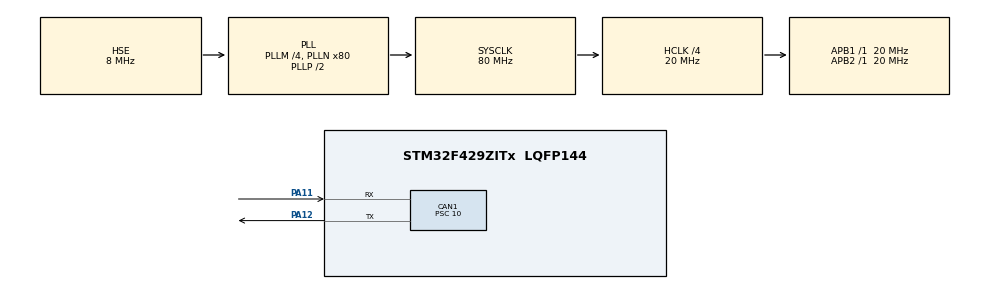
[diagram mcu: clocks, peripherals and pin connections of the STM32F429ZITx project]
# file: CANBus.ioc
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Mcu.Family=STM32F4
RCC.PLLSourceVirtual=RCC_PLLSOURCE_HSE
RCC.CortexFreq_Value=20000000
CAN1.CalculateBaudRate=125000
PA11.Mode=CAN_Activate
RCC.SYSCLKSource=RCC_SYSCLKSOURCE_PLLCLK
ProjectManager.StackSize=0x400
PA13.Signal=SYS_JTMS-SWDIO
PA12.Signal=CAN1_TX
CAN1.BS2=CAN_BS2_6TQ
CAN1.BS1=CAN_BS1_9TQ
ProjectManager.TargetToolchain=STM32CubeIDE
PH0/OSC_IN.Mode=HSE-External-Clock-Source
RCC.HCLKFreq_Value=20000000
RCC.APB2TimFreq_Value=20000000
PH1/OSC_OUT.Signal=RCC_OSC_OUT
RCC.LSE_VALUE=32768
RCC.AHBFreq_Value=20000000
RCC.HSE_VALUE=8000000
PB3.Mode=Trace_Asynchronous_SW
board=STM32F429I-DISC1
RCC.VCOOutputFreq_Value=160000000
PH0/OSC_IN.Signal=RCC_OSC_IN
RCC.APB2Freq_Value=20000000
PA14.Mode=Trace_Asynchronous_SW
RCC.AHBCLKDivider=RCC_SYSCLK_DIV4
PA13.Mode=Trace_Asynchronous_SW
PH1/OSC_OUT.Mode=HSE-External-Clock-Source
Mcu.Name=STM32F429ZITx
RCC.48MHZClocksFreq_Value=53333333.333333336
PB3.Signal=SYS_JTDO-SWO
RCC.SYSCLKFreq_VALUE=80000000
CAN1.Prescaler=10
Mcu.Package=LQFP144
PA12.Mode=CAN_Activate
PA11.Signal=CAN1_RX
PA14.Signal=SYS_JTCK-SWCLK
ProjectManager.HeapSize=0x200
RCC.HSI_VALUE=16000000
RCC.PLLSAIN=50
RCC.PLLQ=3
NVIC.PriorityGroup=NVIC_PRIORITYGROUP_4
RCC.PLLM=4
RCC.PLLN=80
RCC.APB1TimFreq_Value=20000000
RCC.APB1Freq_Value=20000000
CAN1.CalculateTimeBit=8000.00
CAN1.CalculateTimeQuantum=500.0

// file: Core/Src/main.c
/* USER CODE BEGIN Header */
/**
  ******************************************************************************
  * @file           : main.c
  * @brief          : Main program body
  ******************************************************************************
  * @attention
  *
  * <h2><center>&copy; Copyright (c) 2021 STMicroelectronics.
  * All rights reserved.</center></h2>
  *
  * This software component is licensed by ST under Ultimate Liberty license
  * SLA0044, the "License"; You may not use this file except in compliance with
  * the License. You may obtain a copy of the License at:
  *                             www.st.com/SLA0044
  *
  ******************************************************************************
  */
/* USER CODE END Header */
#include "main.h"
#include "can.h"
#include "gpio.h"

/* USER CODE BEGIN PV */
CAN_RxHeaderTypeDef Rxmessage ;
CAN_TxHeaderTypeDef TxMessage ;
CAN_FilterTypeDef FilterInit ;
uint32_t fifo0 = CAN_RX_FIFO0;

uint8_t bootImage[] = {	0x0C,0x94,0x2A,0x00,0x0C,0x94,0x34,0x00,
						0x0C,0x94,0x34,0x00,0x0C,0x94,0x34,0x00,
						0x0C,0x94,0x34,0x00,0x0C,0x94,0x34,0x00,
						0x0C,0x94,0x34,0x00,0x0C,0x94,0x34,0x00,
						0x0C,0x94,0x34,0x00,0x0C,0x94,0x34,0x00,
						0x0C,0x94,0x34,0x00,0x0C,0x94,0x34,0x00,
						0x0C,0x94,0x34,0x00,0x0C,0x94,0x34,0x00,
						0x0C,0x94,0x34,0x00,0x0C,0x94,0x34,0x00,
						0x0C,0x94,0x34,0x00,0x0C,0x94,0x34,0x00,
						0x0C,0x94,0x34,0x00,0x0C,0x94,0x34,0x00,
						0x0C,0x94,0x34,0x00,0x11,0x24,0x1F,0xBE,
						0xCF,0xE5,0xD8,0xE0,0xDE,0xBF,0xCD,0xBF,
						0x0E,0x94,0x36,0x00,0x0C,0x94,0x55,0x00,
						0x0C,0x94,0x00,0x00,0x80,0xE8,0x81,0xBB,
						0x82,0xB3,0x80,0x68,0x82,0xBB,0x2F,0xEF,
						0x83,0xEC,0x99,0xE0,0x21,0x50,0x80,0x40,
						0x90,0x40,0xE1,0xF7,0x00,0xC0,0x00,0x00,
						0x82,0xB3,0x8F,0x77,0x82,0xBB,0x2F,0xEF,
						0x83,0xEC,0x99,0xE0,0x21,0x50,0x80,0x40,
						0x90,0x40,0xE1,0xF7,0x00,0xC0,0x00,0x00,
						0x80,0x9B,0xE6,0xCF,0x0C,0x94,0x00,0x1C,
						0xE3,0xCF,0xF8,0x94,0xFF,0xCF,0xff,0xff,
						0xff,0xff,0xff,0xff,0xff,0xff,0xff,0xff

};

/* USER CODE END PV */

int main(void)
{

  /* MCU Configuration--------------------------------------------------------*/

  /* Reset of all peripherals, Initializes the Flash interface and the Systick. */
  HAL_Init();

  /* Configure the system clock */
  SystemClock_Config();

  /* Initialize all configured peripherals */
  MX_GPIO_Init();
  MX_CAN1_Init();
  /* USER CODE BEGIN 2 */
  FilterInit.FilterActivation = CAN_FILTER_ENABLE ;
  FilterInit.FilterBank = 2;
  FilterInit.FilterFIFOAssignment = CAN_FILTER_FIFO0;
  FilterInit.FilterIdHigh = 0x123<<5;
  FilterInit.FilterIdLow = 0;
  FilterInit.FilterMode = CAN_FILTERMODE_IDLIST;
  FilterInit.FilterScale = CAN_FILTERSCALE_32BIT;
  HAL_CAN_ConfigFilter(&hcan1,&FilterInit);

  uint32_t TxMailbox = CAN_TX_MAILBOX0 ;
  TxMessage.DLC = 8;
  TxMessage.ExtId =0;
  TxMessage.IDE = CAN_ID_STD;
  TxMessage.RTR =0;
  TxMessage.StdId = 0x123;

	 CANSendFirmWare(bootImage,sizeof(bootImage));

  /* USER CODE END 2 */

  /* Infinite loop */
  while (1)
  {

  }
}

void SystemClock_Config(void)
{
  RCC_OscInitTypeDef RCC_OscInitStruct = {0};
  RCC_ClkInitTypeDef RCC_ClkInitStruct = {0};

  /** Configure the main internal regulator output voltage
  */
  __HAL_RCC_PWR_CLK_ENABLE();
  __HAL_PWR_VOLTAGESCALING_CONFIG(PWR_REGULATOR_VOLTAGE_SCALE3);
  /** Initializes the RCC Oscillators according to the specified parameters
  * in the RCC_OscInitTypeDef structure.
  */
  RCC_OscInitStruct.OscillatorType = RCC_OSCILLATORTYPE_HSE;
  RCC_OscInitStruct.HSEState = RCC_HSE_BYPASS;
  RCC_OscInitStruct.PLL.PLLState = RCC_PLL_ON;
  RCC_OscInitStruct.PLL.PLLSource = RCC_PLLSOURCE_HSE;
  RCC_OscInitStruct.PLL.PLLM = 4;
  RCC_OscInitStruct.PLL.PLLN = 80;
  RCC_OscInitStruct.PLL.PLLP = RCC_PLLP_DIV2;
  RCC_OscInitStruct.PLL.PLLQ = 3;
  if (HAL_RCC_OscConfig(&RCC_OscInitStruct) != HAL_OK)
  {
    Error_Handler();
  }
  /** Initializes the CPU, AHB and APB buses clocks
  */
  RCC_ClkInitStruct.ClockType = RCC_CLOCKTYPE_HCLK|RCC_CLOCKTYPE_SYSCLK
                              |RCC_CLOCKTYPE_PCLK1|RCC_CLOCKTYPE_PCLK2;
  RCC_ClkInitStruct.SYSCLKSource = RCC_SYSCLKSOURCE_PLLCLK;
  RCC_ClkInitStruct.AHBCLKDivider = RCC_SYSCLK_DIV4;
  RCC_ClkInitStruct.APB1CLKDivider = RCC_HCLK_DIV1;
  RCC_ClkInitStruct.APB2CLKDivider = RCC_HCLK_DIV1;

  if (HAL_RCC_ClockConfig(&RCC_ClkInitStruct, FLASH_LATENCY_0) != HAL_OK)
  {
    Error_Handler();
  }
}

void Error_Handler(void)
{
  __disable_irq();
  while (1)
  {
  }
}

/************************ (C) COPYRIGHT STMicroelectronics *****END OF FILE****/
